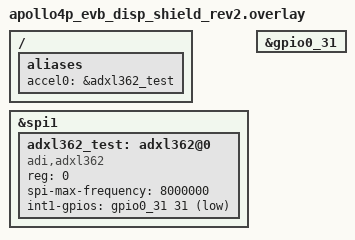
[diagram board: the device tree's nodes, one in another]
/*
 * Copyright (c) 2025, Ambiq Micro Inc. <www.ambiq.com>
 *
 * SPDX-License-Identifier: Apache-2.0
 */

/ {
	aliases {
		accel0 = &adxl362_test;
	};
};

&spi1 {
	status = "okay";

	adxl362_test: adxl362@0 {
		compatible = "adi,adxl362";
		reg = <0>;
		spi-max-frequency = <8000000>;
		int1-gpios = <&gpio0_31 31 (GPIO_ACTIVE_LOW | GPIO_PULL_UP)>;
		status = "okay";
	};
};

&gpio0_31 {
	status = "okay";
};
